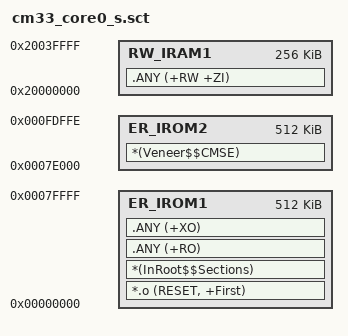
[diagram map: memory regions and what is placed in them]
; *************************************************************
; *** Scatter-Loading Description File generated by uVision ***
; *************************************************************

LR_IROM1 0x0000000 0x00080000  {    ; load region size_region
  ER_IROM1 0x0000000 0x00080000  {  ; load address = execution address
   *.o (RESET, +First)
   *(InRoot$$Sections)
   .ANY (+RO)
   .ANY (+XO)
  }
  RW_IRAM1 0x20000000 0x00040000  {  ; RW data
   .ANY (+RW +ZI)
  }
}

LR_IROM2 0x007E000 0x0007FFFF  {    ; load region size_region
  ER_IROM2 0x007E000 0x0007FFFF  {  ; load address = execution address
   *(Veneer$$CMSE)                   ; check with partition.h
  }
}
